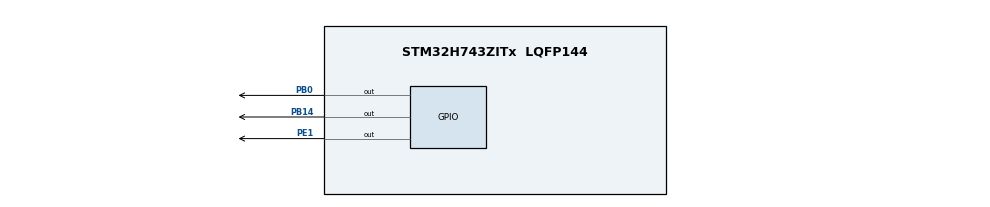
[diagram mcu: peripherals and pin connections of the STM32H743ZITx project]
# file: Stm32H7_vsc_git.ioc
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CORTEX_M7.default_mode_Activation=1
FREERTOS.Tasks01=myTask01,24,128,StartTask01,Default,NULL,Dynamic,NULL,NULL;myTask02,24,128,StartTask02,Default,NULL,Dynamic,NULL,NULL;myTask03,24,128,StartTask03,Default,NULL,Dynamic,NULL,NULL
Mcu.Family=STM32H7
Mcu.Name=STM32H743ZITx
Mcu.Package=LQFP144
NVIC.PriorityGroup=NVIC_PRIORITYGROUP_4
NVIC.TIM6_DAC_IRQn=true\:15\:0\:false\:false\:true\:false\:false\:true\:true
NVIC.TimeBase=TIM6_DAC_IRQn
NVIC.TimeBaseIP=TIM6
PB0.GPIO_ModeDefaultOutputPP=GPIO_MODE_OUTPUT_PP
PB0.GPIO_PuPd=GPIO_PULLDOWN
PB0.GPIO_Speed=GPIO_SPEED_FREQ_MEDIUM
PB0.PinState=GPIO_PIN_RESET
PB0.Signal=GPIO_Output
PB14.GPIO_ModeDefaultOutputPP=GPIO_MODE_OUTPUT_PP
PB14.GPIO_PuPd=GPIO_PULLDOWN
PB14.GPIO_Speed=GPIO_SPEED_FREQ_MEDIUM
PB14.PinState=GPIO_PIN_RESET
PB14.Signal=GPIO_Output
PE1.GPIO_ModeDefaultOutputPP=GPIO_MODE_OUTPUT_PP
PE1.GPIO_PuPd=GPIO_PULLDOWN
PE1.GPIO_Speed=GPIO_SPEED_FREQ_MEDIUM
PE1.PinState=GPIO_PIN_RESET
PE1.Signal=GPIO_Output
PH0-OSC_IN\ (PH0).Mode=HSE-External-Oscillator
PH0-OSC_IN\ (PH0).Signal=RCC_OSC_IN
PH1-OSC_OUT\ (PH1).Mode=HSE-External-Oscillator
PH1-OSC_OUT\ (PH1).Signal=RCC_OSC_OUT
ProjectManager.HeapSize=0x200
ProjectManager.StackSize=0x400
ProjectManager.TargetToolchain=CMake
RCC.ADCFreq_Value=16125000
RCC.APB1Freq_Value=80000000
RCC.APB2Freq_Value=80000000
RCC.APB3Freq_Value=80000000
RCC.APB4Freq_Value=80000000
RCC.CortexFreq_Value=80000000
RCC.DIVM1=1
RCC.DIVN1=20
RCC.HCLKFreq_Value=80000000
RCC.HSE_VALUE=8000000
RCC.PLLFRACN=0
RCC.PLLSourceVirtual=RCC_PLLSOURCE_HSE
RCC.SYSCLKFreq_VALUE=80000000
RCC.SYSCLKSource=RCC_SYSCLKSOURCE_PLLCLK
RCC.USBFreq_Value=80000000
VP_FREERTOS_VS_CMSIS_V2.Mode=CMSIS_V2
VP_MEMORYMAP_VS_MEMORYMAP.Mode=CurAppReg
VP_SYS_VS_tim6.Mode=TIM6
board=custom

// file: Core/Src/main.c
/* USER CODE BEGIN Header */
/**
  ******************************************************************************
  * @file           : main.c
  * @brief          : Main program body
  ******************************************************************************
  * @attention
  *
  * Copyright (c) 2024 STMicroelectronics.
  * All rights reserved.
  *
  * This software is licensed under terms that can be found in the LICENSE file
  * in the root directory of this software component.
  * If no LICENSE file comes with this software, it is provided AS-IS.
  *
  ******************************************************************************
  */
/* USER CODE END Header */
#include "main.h"
#include "cmsis_os.h"

/* Definitions for myTask01 */
osThreadId_t myTask01Handle;
const osThreadAttr_t myTask01_attributes = {
  .name = "myTask01",
  .stack_size = 128 * 4,
  .priority = (osPriority_t) osPriorityNormal,
};
/* Definitions for myTask02 */
osThreadId_t myTask02Handle;
const osThreadAttr_t myTask02_attributes = {
  .name = "myTask02",
  .stack_size = 128 * 4,
  .priority = (osPriority_t) osPriorityNormal,
};
/* Definitions for myTask03 */
osThreadId_t myTask03Handle;
const osThreadAttr_t myTask03_attributes = {
  .name = "myTask03",
  .stack_size = 128 * 4,
  .priority = (osPriority_t) osPriorityNormal,
};

void SystemClock_Config(void);
static void MPU_Config(void);
static void MX_GPIO_Init(void);
void StartTask01(void *argument);
void StartTask02(void *argument);
void StartTask03(void *argument);

int main(void)
{

  /* MPU Configuration--------------------------------------------------------*/
  MPU_Config();

  /* MCU Configuration--------------------------------------------------------*/

  /* Reset of all peripherals, Initializes the Flash interface and the Systick. */
  HAL_Init();

  /* Configure the system clock */
  SystemClock_Config();

  /* Initialize all configured peripherals */
  MX_GPIO_Init();

  /* Init scheduler */
  osKernelInitialize();

  /* Create the thread(s) */
  /* creation of myTask01 */
  myTask01Handle = osThreadNew(StartTask01, NULL, &myTask01_attributes);

  /* creation of myTask02 */
  myTask02Handle = osThreadNew(StartTask02, NULL, &myTask02_attributes);

  /* creation of myTask03 */
  myTask03Handle = osThreadNew(StartTask03, NULL, &myTask03_attributes);

  /* Start scheduler */
  osKernelStart();

  /* We should never get here as control is now taken by the scheduler */

  /* Infinite loop */
  while (1)
  {

    /* USER CODE BEGIN 3 */

    /*
    HAL_GPIO_TogglePin(GPIOB, GPIO_PIN_0|GPIO_PIN_14);
    HAL_GPIO_TogglePin(GPIOE, GPIO_PIN_1);
    HAL_Delay(250);
    */

  }
  /* USER CODE END 3 */
}

void SystemClock_Config(void)
{
  RCC_OscInitTypeDef RCC_OscInitStruct = {0};
  RCC_ClkInitTypeDef RCC_ClkInitStruct = {0};

  /** Supply configuration update enable
  */
  HAL_PWREx_ConfigSupply(PWR_LDO_SUPPLY);

  /** Configure the main internal regulator output voltage
  */
  __HAL_PWR_VOLTAGESCALING_CONFIG(PWR_REGULATOR_VOLTAGE_SCALE3);

  while(!__HAL_PWR_GET_FLAG(PWR_FLAG_VOSRDY)) {}

  /** Initializes the RCC Oscillators according to the specified parameters
  * in the RCC_OscInitTypeDef structure.
  */
  RCC_OscInitStruct.OscillatorType = RCC_OSCILLATORTYPE_HSE;
  RCC_OscInitStruct.HSEState = RCC_HSE_ON;
  RCC_OscInitStruct.PLL.PLLState = RCC_PLL_ON;
  RCC_OscInitStruct.PLL.PLLSource = RCC_PLLSOURCE_HSE;
  RCC_OscInitStruct.PLL.PLLM = 1;
  RCC_OscInitStruct.PLL.PLLN = 20;
  RCC_OscInitStruct.PLL.PLLP = 2;
  RCC_OscInitStruct.PLL.PLLQ = 2;
  RCC_OscInitStruct.PLL.PLLR = 2;
  RCC_OscInitStruct.PLL.PLLRGE = RCC_PLL1VCIRANGE_3;
  RCC_OscInitStruct.PLL.PLLVCOSEL = RCC_PLL1VCOMEDIUM;
  RCC_OscInitStruct.PLL.PLLFRACN = 0;
  if (HAL_RCC_OscConfig(&RCC_OscInitStruct) != HAL_OK)
  {
    Error_Handler();
  }

  /** Initializes the CPU, AHB and APB buses clocks
  */
  RCC_ClkInitStruct.ClockType = RCC_CLOCKTYPE_HCLK|RCC_CLOCKTYPE_SYSCLK
                              |RCC_CLOCKTYPE_PCLK1|RCC_CLOCKTYPE_PCLK2
                              |RCC_CLOCKTYPE_D3PCLK1|RCC_CLOCKTYPE_D1PCLK1;
  RCC_ClkInitStruct.SYSCLKSource = RCC_SYSCLKSOURCE_PLLCLK;
  RCC_ClkInitStruct.SYSCLKDivider = RCC_SYSCLK_DIV1;
  RCC_ClkInitStruct.AHBCLKDivider = RCC_HCLK_DIV1;
  RCC_ClkInitStruct.APB3CLKDivider = RCC_APB3_DIV1;
  RCC_ClkInitStruct.APB1CLKDivider = RCC_APB1_DIV1;
  RCC_ClkInitStruct.APB2CLKDivider = RCC_APB2_DIV1;
  RCC_ClkInitStruct.APB4CLKDivider = RCC_APB4_DIV1;

  if (HAL_RCC_ClockConfig(&RCC_ClkInitStruct, FLASH_LATENCY_1) != HAL_OK)
  {
    Error_Handler();
  }
}

static void MX_GPIO_Init(void)
{
  GPIO_InitTypeDef GPIO_InitStruct = {0};

  /* GPIO Ports Clock Enable */
  __HAL_RCC_GPIOH_CLK_ENABLE();
  __HAL_RCC_GPIOB_CLK_ENABLE();
  __HAL_RCC_GPIOE_CLK_ENABLE();

  /*Configure GPIO pin Output Level */
  HAL_GPIO_WritePin(GPIOB, GPIO_PIN_0|GPIO_PIN_14, GPIO_PIN_RESET);

  /*Configure GPIO pin Output Level */
  HAL_GPIO_WritePin(GPIOE, GPIO_PIN_1, GPIO_PIN_RESET);

  /*Configure GPIO pins : PB0 PB14 */
  GPIO_InitStruct.Pin = GPIO_PIN_0|GPIO_PIN_14;
  GPIO_InitStruct.Mode = GPIO_MODE_OUTPUT_PP;
  GPIO_InitStruct.Pull = GPIO_PULLDOWN;
  GPIO_InitStruct.Speed = GPIO_SPEED_FREQ_MEDIUM;
  HAL_GPIO_Init(GPIOB, &GPIO_InitStruct);

  /*Configure GPIO pin : PE1 */
  GPIO_InitStruct.Pin = GPIO_PIN_1;
  GPIO_InitStruct.Mode = GPIO_MODE_OUTPUT_PP;
  GPIO_InitStruct.Pull = GPIO_PULLDOWN;
  GPIO_InitStruct.Speed = GPIO_SPEED_FREQ_MEDIUM;
  HAL_GPIO_Init(GPIOE, &GPIO_InitStruct);

}

void StartTask01(void *argument)
{
  for(;;)
  {
    osDelay(1);
  }
}

void StartTask02(void *argument)
{
  for(;;)
  {
    osDelay(1);
  }
}

void StartTask03(void *argument)
{
  for(;;)
  {
    osDelay(1);
  }
}

 /* MPU Configuration */

void MPU_Config(void)
{
  MPU_Region_InitTypeDef MPU_InitStruct = {0};

  /* Disables the MPU */
  HAL_MPU_Disable();

  /** Initializes and configures the Region and the memory to be protected
  */
  MPU_InitStruct.Enable = MPU_REGION_ENABLE;
  MPU_InitStruct.Number = MPU_REGION_NUMBER0;
  MPU_InitStruct.BaseAddress = 0x0;
  MPU_InitStruct.Size = MPU_REGION_SIZE_4GB;
  MPU_InitStruct.SubRegionDisable = 0x87;
  MPU_InitStruct.TypeExtField = MPU_TEX_LEVEL0;
  MPU_InitStruct.AccessPermission = MPU_REGION_NO_ACCESS;
  MPU_InitStruct.DisableExec = MPU_INSTRUCTION_ACCESS_DISABLE;
  MPU_InitStruct.IsShareable = MPU_ACCESS_SHAREABLE;
  MPU_InitStruct.IsCacheable = MPU_ACCESS_NOT_CACHEABLE;
  MPU_InitStruct.IsBufferable = MPU_ACCESS_NOT_BUFFERABLE;

  HAL_MPU_ConfigRegion(&MPU_InitStruct);
  /* Enables the MPU */
  HAL_MPU_Enable(MPU_PRIVILEGED_DEFAULT);

}

void HAL_TIM_PeriodElapsedCallback(TIM_HandleTypeDef *htim)
{
  if (htim->Instance == TIM6) {
    HAL_IncTick();
  }
}

void Error_Handler(void)
{
  __disable_irq();
  while (1)
  {
  }
}
